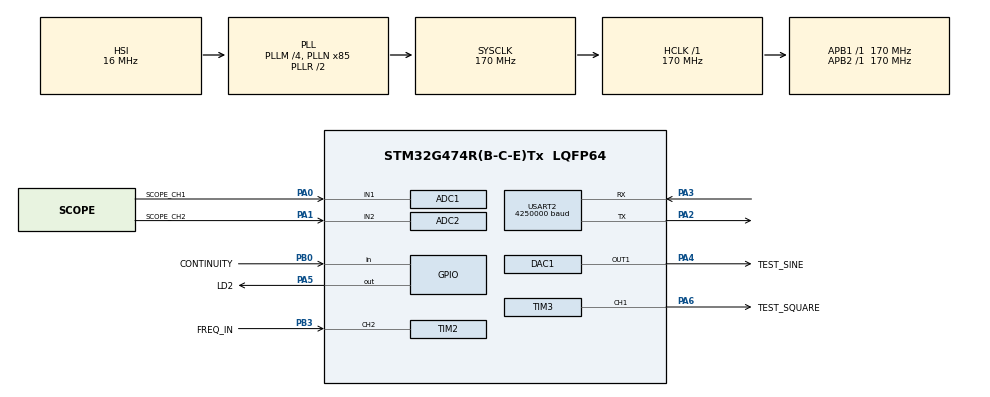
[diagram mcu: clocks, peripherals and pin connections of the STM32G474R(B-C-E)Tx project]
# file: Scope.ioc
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ADC1.Channel-0\#ChannelRegularConversion=ADC_CHANNEL_1
ADC1.ClockPrescaler=ADC_CLOCK_SYNC_PCLK_DIV4
ADC1.ContinuousConvMode=DISABLE
ADC1.DMAContinuousRequests=DISABLE
ADC1.DataAlign=ADC_DATAALIGN_RIGHT
ADC1.DiscontinuousConvMode=DISABLE
ADC1.EOCSelection=ADC_EOC_SINGLE_CONV
ADC1.EnableInjectedConversion=DISABLE
ADC1.EnableRegularConversion=ENABLE
ADC1.ExternalTrigConv=ADC_EXTERNALTRIG_T6_TRGO
ADC1.ExternalTrigConvEdge=ADC_EXTERNALTRIGCONVEDGE_RISING
ADC1.LowPowerAutoWait=DISABLE
ADC1.Mode=ADC_MODE_INDEPENDENT
ADC1.NbrOfConversion=1
ADC1.OffsetNumber-0\#ChannelRegularConversion=ADC_OFFSET_NONE
ADC1.Overrun=ADC_OVR_DATA_OVERWRITTEN
ADC1.OversamplingMode=DISABLE
ADC1.Rank-0\#ChannelRegularConversion=1
ADC1.Resolution=ADC_RESOLUTION_12B
ADC1.SamplingTime-0\#ChannelRegularConversion=ADC_SAMPLETIME_6CYCLES_5
ADC1.ScanConvMode=ADC_SCAN_DISABLE
ADC1.master=1
ADC2.Channel-0\#ChannelRegularConversion=ADC_CHANNEL_2
ADC2.ClockPrescaler=ADC_CLOCK_SYNC_PCLK_DIV4
ADC2.ContinuousConvMode=DISABLE
ADC2.DMAContinuousRequests=DISABLE
ADC2.DataAlign=ADC_DATAALIGN_RIGHT
ADC2.DiscontinuousConvMode=DISABLE
ADC2.EOCSelection=ADC_EOC_SINGLE_CONV
ADC2.EnableInjectedConversion=DISABLE
ADC2.EnableRegularConversion=ENABLE
ADC2.ExternalTrigConv=ADC_EXTERNALTRIG_T6_TRGO
ADC2.ExternalTrigConvEdge=ADC_EXTERNALTRIGCONVEDGE_RISING
ADC2.LowPowerAutoWait=DISABLE
ADC2.NbrOfConversion=1
ADC2.OffsetNumber-0\#ChannelRegularConversion=ADC_OFFSET_NONE
ADC2.Overrun=ADC_OVR_DATA_OVERWRITTEN
ADC2.OversamplingMode=DISABLE
ADC2.Rank-0\#ChannelRegularConversion=1
ADC2.Resolution=ADC_RESOLUTION_12B
ADC2.SamplingTime-0\#ChannelRegularConversion=ADC_SAMPLETIME_6CYCLES_5
ADC2.ScanConvMode=ADC_SCAN_DISABLE
ADC5.Channel-0\#ChannelRegularConversion=ADC_CHANNEL_VREFINT
ADC5.ClockPrescaler=ADC_CLOCK_SYNC_PCLK_DIV4
ADC5.ContinuousConvMode=DISABLE
ADC5.ExternalTrigConv=ADC_SOFTWARE_START
ADC5.NbrOfConversion=1
ADC5.OffsetNumber-0\#ChannelRegularConversion=ADC_OFFSET_NONE
ADC5.Rank-0\#ChannelRegularConversion=1
ADC5.SamplingTime-0\#ChannelRegularConversion=ADC_SAMPLETIME_640CYCLES_5
DAC1.DAC_Trigger_OUT1-DAC_OUT1=DAC_TRIGGER_T7_TRGO
Dma.ADC1.0.Direction=DMA_PERIPH_TO_MEMORY
Dma.ADC1.0.EventEnable=DISABLE
Dma.ADC1.0.Instance=DMA1_Channel1
Dma.ADC1.0.MemDataAlignment=DMA_MDATAALIGN_HALFWORD
Dma.ADC1.0.MemInc=DMA_MINC_ENABLE
Dma.ADC1.0.Mode=DMA_NORMAL
Dma.ADC1.0.PeriphDataAlignment=DMA_PDATAALIGN_HALFWORD
Dma.ADC1.0.PeriphInc=DMA_PINC_DISABLE
Dma.ADC1.0.Polarity=HAL_DMAMUX_REQ_GEN_RISING
Dma.ADC1.0.Priority=DMA_PRIORITY_HIGH
Dma.ADC1.0.RequestNumber=1
Dma.ADC1.0.SignalID=NONE
Dma.ADC1.0.SyncEnable=DISABLE
Dma.ADC1.0.SyncPolarity=HAL_DMAMUX_SYNC_NO_EVENT
Dma.ADC1.0.SyncRequestNumber=1
Dma.ADC1.0.SyncSignalID=NONE
Dma.ADC2.1.Direction=DMA_PERIPH_TO_MEMORY
Dma.ADC2.1.EventEnable=DISABLE
Dma.ADC2.1.Instance=DMA1_Channel2
Dma.ADC2.1.MemDataAlignment=DMA_MDATAALIGN_HALFWORD
Dma.ADC2.1.MemInc=DMA_MINC_ENABLE
Dma.ADC2.1.Mode=DMA_NORMAL
Dma.ADC2.1.PeriphDataAlignment=DMA_PDATAALIGN_HALFWORD
Dma.ADC2.1.PeriphInc=DMA_PINC_DISABLE
Dma.ADC2.1.Polarity=HAL_DMAMUX_REQ_GEN_RISING
Dma.ADC2.1.Priority=DMA_PRIORITY_HIGH
Dma.ADC2.1.RequestNumber=1
Dma.ADC2.1.SignalID=NONE
Dma.ADC2.1.SyncEnable=DISABLE
Dma.ADC2.1.SyncPolarity=HAL_DMAMUX_SYNC_NO_EVENT
Dma.ADC2.1.SyncRequestNumber=1
Dma.ADC2.1.SyncSignalID=NONE
Dma.DAC1_CH1.2.Direction=DMA_MEMORY_TO_PERIPH
Dma.DAC1_CH1.2.EventEnable=DISABLE
Dma.DAC1_CH1.2.Instance=DMA1_Channel3
Dma.DAC1_CH1.2.MemDataAlignment=DMA_MDATAALIGN_HALFWORD
Dma.DAC1_CH1.2.MemInc=DMA_MINC_ENABLE
Dma.DAC1_CH1.2.Mode=DMA_CIRCULAR
Dma.DAC1_CH1.2.PeriphDataAlignment=DMA_PDATAALIGN_WORD
Dma.DAC1_CH1.2.PeriphInc=DMA_PINC_DISABLE
Dma.DAC1_CH1.2.Polarity=HAL_DMAMUX_REQ_GEN_RISING
Dma.DAC1_CH1.2.Priority=DMA_PRIORITY_LOW
Dma.DAC1_CH1.2.RequestNumber=1
Dma.DAC1_CH1.2.SignalID=NONE
Dma.DAC1_CH1.2.SyncEnable=DISABLE
Dma.DAC1_CH1.2.SyncPolarity=HAL_DMAMUX_SYNC_NO_EVENT
Dma.DAC1_CH1.2.SyncRequestNumber=1
Dma.DAC1_CH1.2.SyncSignalID=NONE
Dma.Request0=ADC1
Dma.Request1=ADC2
Dma.Request2=DAC1_CH1
Mcu.Family=STM32G4
Mcu.Name=STM32G474R(B-C-E)Tx
Mcu.Package=LQFP64
NVIC.DMA1_Channel1_IRQn=true\:0\:0\:false\:false\:true\:false\:true\:true
NVIC.DMA1_Channel2_IRQn=true\:0\:0\:false\:false\:true\:false\:true\:true
NVIC.DMA1_Channel3_IRQn=true\:0\:0\:false\:false\:true\:false\:true\:true
NVIC.PriorityGroup=NVIC_PRIORITYGROUP_4
NVIC.USART2_IRQn=true\:0\:0\:false\:false\:true\:true\:true\:true
PA0.GPIO_Label=SCOPE_CH1
PA0.Mode=IN1-Single-Ended
PA0.Signal=ADC1_IN1
PA1.GPIO_Label=SCOPE_CH2
PA1.Mode=IN2-Single-Ended
PA1.Signal=ADC2_IN2
PA2.Mode=Asynchronous
PA2.Signal=USART2_TX
PA3.Mode=Asynchronous
PA3.Signal=USART2_RX
PA4.GPIO_Label=TEST_SINE
PA4.Signal=COMP_DAC11_group
PA5.GPIO_Label=LD2
PA5.Signal=GPIO_Output
PA6.GPIO_Label=TEST_SQUARE
PA6.Signal=S_TIM3_CH1
PB0.GPIO_Label=CONTINUITY
PB0.GPIO_PuPd=GPIO_PULLUP
PB0.Signal=GPIO_Input
PB3.GPIO_Label=FREQ_IN
PB3.GPIO_PuPd=GPIO_PULLDOWN
PB3.Signal=S_TIM2_CH2
ProjectManager.HeapSize=0x200
ProjectManager.StackSize=0x800
ProjectManager.TargetToolchain=STM32CubeIDE
RCC.ADC12Freq_Value=170000000
RCC.ADC345Freq_Value=170000000
RCC.AHBFreq_Value=170000000
RCC.APB1Freq_Value=170000000
RCC.APB1TimFreq_Value=170000000
RCC.APB2Freq_Value=170000000
RCC.APB2TimFreq_Value=170000000
RCC.CortexFreq_Value=170000000
RCC.EXTERNAL_CLOCK_VALUE=12288000
RCC.HCLKFreq_Value=170000000
RCC.HSE_VALUE=8000000
RCC.HSI48_VALUE=48000000
RCC.HSI_VALUE=16000000
RCC.LSE_VALUE=32768
RCC.PLLM=RCC_PLLM_DIV4
RCC.PLLN=85
RCC.SYSCLKFreq_VALUE=170000000
RCC.SYSCLKSource=RCC_SYSCLKSOURCE_PLLCLK
RCC.USBFreq_Value=170000000
RCC.VCOOutputFreq_Value=340000000
SH.COMP_DAC11_group.0=DAC1_OUT1,DAC_OUT1
SH.S_TIM2_CH2.0=TIM2_CH2,TriggerSource_TI2FP2
SH.S_TIM2_CH2.1=TIM2_CH2,Input_Capture2_from_TI2
SH.S_TIM2_CH2.2=TIM2_CH2,Input_Capture1_from_TI2
SH.S_TIM3_CH1.0=TIM3_CH1,PWM Generation1 CH1
TIM2.Channel-Input_Capture1_from_TI2=TIM_CHANNEL_1
TIM2.Channel-Input_Capture2_from_TI2=TIM_CHANNEL_2
TIM2.ICPolarity_CH1=TIM_INPUTCHANNELPOLARITY_FALLING
TIM2.ICPolarity_CH2=TIM_INPUTCHANNELPOLARITY_RISING
TIM2.ICSelection-Input_Capture1_from_TI2=TIM_ICSELECTION_INDIRECTTI
TIM2.ICSelection-Input_Capture2_from_TI2=TIM_ICSELECTION_DIRECTTI
TIM2.Period=4294967295
TIM2.Prescaler=0
TIM2.TIM_SlaveMode=TIM_SLAVEMODE_RESET
TIM3.Channel-PWM\ Generation1\ CH1=TIM_CHANNEL_1
TIM3.PeriodNoDither=4999
TIM3.Prescaler=16
TIM3.PulseNoDither_1=1250
TIM6.PeriodNoDither=9
TIM6.Prescaler=16
TIM6.TIM_MasterOutputTrigger=TIM_TRGO_UPDATE
TIM7.PeriodNoDither=1699
TIM7.Prescaler=0
TIM7.TIM_MasterOutputTrigger=TIM_TRGO_UPDATE
USART2.BaudRate=4250000
USART2.VirtualMode-Asynchronous=VM_ASYNC
VP_ADC5_Vref_Input.Mode=IN-Vrefint
VP_SYS_VS_DBSignals.Mode=DisableDeadBatterySignals
VP_TIM2_VS_ControllerModeReset.Mode=Reset Mode
VP_TIM3_VS_ClockSourceINT.Mode=Internal
VP_TIM6_VS_ClockSourceINT.Mode=Enable_Timer
VP_TIM7_VS_ClockSourceINT.Mode=Enable_Timer
board=custom

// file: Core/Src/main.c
/* USER CODE BEGIN Header */
/**
  ******************************************************************************
  * @file           : main.c
  * @brief          : Main program body
  ******************************************************************************
  * @attention
  *
  * Copyright (c) 2026 STMicroelectronics.
  * All rights reserved.
  *
  * This software is licensed under terms that can be found in the LICENSE file
  * in the root directory of this software component.
  * If no LICENSE file comes with this software, it is provided AS-IS.
  *
  ******************************************************************************
  */
/* USER CODE END Header */
#include "main.h"

/* USER CODE BEGIN Includes */
#include "scope.h"
#include "test_signals.h"

/* USER CODE END Includes */

ADC_HandleTypeDef hadc1;
ADC_HandleTypeDef hadc2;
ADC_HandleTypeDef hadc5;
DMA_HandleTypeDef hdma_adc1;
DMA_HandleTypeDef hdma_adc2;

DAC_HandleTypeDef hdac1;
DMA_HandleTypeDef hdma_dac1_ch1;

TIM_HandleTypeDef htim2;
TIM_HandleTypeDef htim3;
TIM_HandleTypeDef htim6;
TIM_HandleTypeDef htim7;

UART_HandleTypeDef huart2;

void SystemClock_Config(void);
static void MX_GPIO_Init(void);
static void MX_DMA_Init(void);
static void MX_USART2_UART_Init(void);
static void MX_ADC1_Init(void);
static void MX_ADC2_Init(void);
static void MX_ADC5_Init(void);
static void MX_DAC1_Init(void);
static void MX_TIM2_Init(void);
static void MX_TIM3_Init(void);
static void MX_TIM6_Init(void);
static void MX_TIM7_Init(void);

int main(void)
{

  /* MCU Configuration--------------------------------------------------------*/

  /* Reset of all peripherals, Initializes the Flash interface and the Systick. */
  HAL_Init();

  /* Configure the system clock */
  SystemClock_Config();

  /* Initialize all configured peripherals */
  MX_GPIO_Init();
  MX_DMA_Init();
  MX_USART2_UART_Init();
  MX_ADC1_Init();
  MX_ADC2_Init();
  MX_ADC5_Init();
  MX_DAC1_Init();
  MX_TIM2_Init();
  MX_TIM3_Init();
  MX_TIM6_Init();
  MX_TIM7_Init();
  /* USER CODE BEGIN 2 */
  test_signals_start();   /* sine on A2, square on D12 */
  scope_init();

  /* USER CODE END 2 */

  /* Infinite loop */
  while (1)
  {

    /* USER CODE BEGIN 3 */
    scope_run();          /* measure once and send it to the PC */
  }
  /* USER CODE END 3 */
}

void SystemClock_Config(void)
{
  RCC_OscInitTypeDef RCC_OscInitStruct = {0};
  RCC_ClkInitTypeDef RCC_ClkInitStruct = {0};

  /** Configure the main internal regulator output voltage
  */
  HAL_PWREx_ControlVoltageScaling(PWR_REGULATOR_VOLTAGE_SCALE1_BOOST);

  /** Initializes the RCC Oscillators according to the specified parameters
  * in the RCC_OscInitTypeDef structure.
  */
  RCC_OscInitStruct.OscillatorType = RCC_OSCILLATORTYPE_HSI;
  RCC_OscInitStruct.HSIState = RCC_HSI_ON;
  RCC_OscInitStruct.HSICalibrationValue = RCC_HSICALIBRATION_DEFAULT;
  RCC_OscInitStruct.PLL.PLLState = RCC_PLL_ON;
  RCC_OscInitStruct.PLL.PLLSource = RCC_PLLSOURCE_HSI;
  RCC_OscInitStruct.PLL.PLLM = RCC_PLLM_DIV4;
  RCC_OscInitStruct.PLL.PLLN = 85;
  RCC_OscInitStruct.PLL.PLLP = RCC_PLLP_DIV2;
  RCC_OscInitStruct.PLL.PLLQ = RCC_PLLQ_DIV2;
  RCC_OscInitStruct.PLL.PLLR = RCC_PLLR_DIV2;
  if (HAL_RCC_OscConfig(&RCC_OscInitStruct) != HAL_OK)
  {
    Error_Handler();
  }

  /** Initializes the CPU, AHB and APB buses clocks
  */
  RCC_ClkInitStruct.ClockType = RCC_CLOCKTYPE_HCLK|RCC_CLOCKTYPE_SYSCLK
                              |RCC_CLOCKTYPE_PCLK1|RCC_CLOCKTYPE_PCLK2;
  RCC_ClkInitStruct.SYSCLKSource = RCC_SYSCLKSOURCE_PLLCLK;
  RCC_ClkInitStruct.AHBCLKDivider = RCC_SYSCLK_DIV1;
  RCC_ClkInitStruct.APB1CLKDivider = RCC_HCLK_DIV1;
  RCC_ClkInitStruct.APB2CLKDivider = RCC_HCLK_DIV1;

  if (HAL_RCC_ClockConfig(&RCC_ClkInitStruct, FLASH_LATENCY_4) != HAL_OK)
  {
    Error_Handler();
  }
}

static void MX_ADC1_Init(void)
{

  ADC_MultiModeTypeDef multimode = {0};
  ADC_ChannelConfTypeDef sConfig = {0};

  /** Common config
  */
  hadc1.Instance = ADC1;
  hadc1.Init.ClockPrescaler = ADC_CLOCK_SYNC_PCLK_DIV4;
  hadc1.Init.Resolution = ADC_RESOLUTION_12B;
  hadc1.Init.DataAlign = ADC_DATAALIGN_RIGHT;
  hadc1.Init.GainCompensation = 0;
  hadc1.Init.ScanConvMode = ADC_SCAN_DISABLE;
  hadc1.Init.EOCSelection = ADC_EOC_SINGLE_CONV;
  hadc1.Init.LowPowerAutoWait = DISABLE;
  hadc1.Init.ContinuousConvMode = DISABLE;
  hadc1.Init.NbrOfConversion = 1;
  hadc1.Init.DiscontinuousConvMode = DISABLE;
  hadc1.Init.ExternalTrigConv = ADC_EXTERNALTRIG_T6_TRGO;
  hadc1.Init.ExternalTrigConvEdge = ADC_EXTERNALTRIGCONVEDGE_RISING;
  hadc1.Init.DMAContinuousRequests = DISABLE;
  hadc1.Init.Overrun = ADC_OVR_DATA_OVERWRITTEN;
  hadc1.Init.OversamplingMode = DISABLE;
  if (HAL_ADC_Init(&hadc1) != HAL_OK)
  {
    Error_Handler();
  }

  /** Configure the ADC multi-mode
  */
  multimode.Mode = ADC_MODE_INDEPENDENT;
  if (HAL_ADCEx_MultiModeConfigChannel(&hadc1, &multimode) != HAL_OK)
  {
    Error_Handler();
  }

  /** Configure Regular Channel
  */
  sConfig.Channel = ADC_CHANNEL_1;
  sConfig.Rank = ADC_REGULAR_RANK_1;
  sConfig.SamplingTime = ADC_SAMPLETIME_6CYCLES_5;
  sConfig.SingleDiff = ADC_SINGLE_ENDED;
  sConfig.OffsetNumber = ADC_OFFSET_NONE;
  sConfig.Offset = 0;
  if (HAL_ADC_ConfigChannel(&hadc1, &sConfig) != HAL_OK)
  {
    Error_Handler();
  }

}

static void MX_ADC2_Init(void)
{

  ADC_ChannelConfTypeDef sConfig = {0};

  /** Common config
  */
  hadc2.Instance = ADC2;
  hadc2.Init.ClockPrescaler = ADC_CLOCK_SYNC_PCLK_DIV4;
  hadc2.Init.Resolution = ADC_RESOLUTION_12B;
  hadc2.Init.DataAlign = ADC_DATAALIGN_RIGHT;
  hadc2.Init.GainCompensation = 0;
  hadc2.Init.ScanConvMode = ADC_SCAN_DISABLE;
  hadc2.Init.EOCSelection = ADC_EOC_SINGLE_CONV;
  hadc2.Init.LowPowerAutoWait = DISABLE;
  hadc2.Init.ContinuousConvMode = DISABLE;
  hadc2.Init.NbrOfConversion = 1;
  hadc2.Init.DiscontinuousConvMode = DISABLE;
  hadc2.Init.ExternalTrigConv = ADC_EXTERNALTRIG_T6_TRGO;
  hadc2.Init.ExternalTrigConvEdge = ADC_EXTERNALTRIGCONVEDGE_RISING;
  hadc2.Init.DMAContinuousRequests = DISABLE;
  hadc2.Init.Overrun = ADC_OVR_DATA_OVERWRITTEN;
  hadc2.Init.OversamplingMode = DISABLE;
  if (HAL_ADC_Init(&hadc2) != HAL_OK)
  {
    Error_Handler();
  }

  /** Configure Regular Channel
  */
  sConfig.Channel = ADC_CHANNEL_2;
  sConfig.Rank = ADC_REGULAR_RANK_1;
  sConfig.SamplingTime = ADC_SAMPLETIME_6CYCLES_5;
  sConfig.SingleDiff = ADC_SINGLE_ENDED;
  sConfig.OffsetNumber = ADC_OFFSET_NONE;
  sConfig.Offset = 0;
  if (HAL_ADC_ConfigChannel(&hadc2, &sConfig) != HAL_OK)
  {
    Error_Handler();
  }

}

static void MX_ADC5_Init(void)
{

  ADC_ChannelConfTypeDef sConfig = {0};

  /** Common config
  */
  hadc5.Instance = ADC5;
  hadc5.Init.ClockPrescaler = ADC_CLOCK_SYNC_PCLK_DIV4;
  hadc5.Init.Resolution = ADC_RESOLUTION_12B;
  hadc5.Init.DataAlign = ADC_DATAALIGN_RIGHT;
  hadc5.Init.GainCompensation = 0;
  hadc5.Init.ScanConvMode = ADC_SCAN_DISABLE;
  hadc5.Init.EOCSelection = ADC_EOC_SINGLE_CONV;
  hadc5.Init.LowPowerAutoWait = DISABLE;
  hadc5.Init.ContinuousConvMode = DISABLE;
  hadc5.Init.NbrOfConversion = 1;
  hadc5.Init.DiscontinuousConvMode = DISABLE;
  hadc5.Init.ExternalTrigConv = ADC_SOFTWARE_START;
  hadc5.Init.ExternalTrigConvEdge = ADC_EXTERNALTRIGCONVEDGE_NONE;
  hadc5.Init.DMAContinuousRequests = DISABLE;
  hadc5.Init.Overrun = ADC_OVR_DATA_PRESERVED;
  hadc5.Init.OversamplingMode = DISABLE;
  if (HAL_ADC_Init(&hadc5) != HAL_OK)
  {
    Error_Handler();
  }

  /** Configure Regular Channel
  */
  sConfig.Channel = ADC_CHANNEL_VREFINT;
  sConfig.Rank = ADC_REGULAR_RANK_1;
  sConfig.SamplingTime = ADC_SAMPLETIME_640CYCLES_5;
  sConfig.SingleDiff = ADC_SINGLE_ENDED;
  sConfig.OffsetNumber = ADC_OFFSET_NONE;
  sConfig.Offset = 0;
  if (HAL_ADC_ConfigChannel(&hadc5, &sConfig) != HAL_OK)
  {
    Error_Handler();
  }

}

static void MX_DAC1_Init(void)
{

  DAC_ChannelConfTypeDef sConfig = {0};

  /** DAC Initialization
  */
  hdac1.Instance = DAC1;
  if (HAL_DAC_Init(&hdac1) != HAL_OK)
  {
    Error_Handler();
  }

  /** DAC channel OUT1 config
  */
  sConfig.DAC_HighFrequency = DAC_HIGH_FREQUENCY_INTERFACE_MODE_AUTOMATIC;
  sConfig.DAC_DMADoubleDataMode = DISABLE;
  sConfig.DAC_SignedFormat = DISABLE;
  sConfig.DAC_SampleAndHold = DAC_SAMPLEANDHOLD_DISABLE;
  sConfig.DAC_Trigger = DAC_TRIGGER_T7_TRGO;
  sConfig.DAC_Trigger2 = DAC_TRIGGER_NONE;
  sConfig.DAC_OutputBuffer = DAC_OUTPUTBUFFER_ENABLE;
  sConfig.DAC_ConnectOnChipPeripheral = DAC_CHIPCONNECT_EXTERNAL;
  sConfig.DAC_UserTrimming = DAC_TRIMMING_FACTORY;
  if (HAL_DAC_ConfigChannel(&hdac1, &sConfig, DAC_CHANNEL_1) != HAL_OK)
  {
    Error_Handler();
  }

}

static void MX_TIM2_Init(void)
{

  TIM_SlaveConfigTypeDef sSlaveConfig = {0};
  TIM_MasterConfigTypeDef sMasterConfig = {0};
  TIM_IC_InitTypeDef sConfigIC = {0};

  htim2.Instance = TIM2;
  htim2.Init.Prescaler = 0;
  htim2.Init.CounterMode = TIM_COUNTERMODE_UP;
  htim2.Init.Period = 4294967295;
  htim2.Init.ClockDivision = TIM_CLOCKDIVISION_DIV1;
  htim2.Init.AutoReloadPreload = TIM_AUTORELOAD_PRELOAD_DISABLE;
  if (HAL_TIM_Base_Init(&htim2) != HAL_OK)
  {
    Error_Handler();
  }
  if (HAL_TIM_IC_Init(&htim2) != HAL_OK)
  {
    Error_Handler();
  }
  sSlaveConfig.SlaveMode = TIM_SLAVEMODE_RESET;
  sSlaveConfig.InputTrigger = TIM_TS_TI2FP2;
  sSlaveConfig.TriggerPolarity = TIM_INPUTCHANNELPOLARITY_RISING;
  sSlaveConfig.TriggerFilter = 0;
  if (HAL_TIM_SlaveConfigSynchro(&htim2, &sSlaveConfig) != HAL_OK)
  {
    Error_Handler();
  }
  sMasterConfig.MasterOutputTrigger = TIM_TRGO_RESET;
  sMasterConfig.MasterSlaveMode = TIM_MASTERSLAVEMODE_DISABLE;
  if (HAL_TIMEx_MasterConfigSynchronization(&htim2, &sMasterConfig) != HAL_OK)
  {
    Error_Handler();
  }
  sConfigIC.ICPolarity = TIM_INPUTCHANNELPOLARITY_FALLING;
  sConfigIC.ICSelection = TIM_ICSELECTION_INDIRECTTI;
  sConfigIC.ICPrescaler = TIM_ICPSC_DIV1;
  sConfigIC.ICFilter = 0;
  if (HAL_TIM_IC_ConfigChannel(&htim2, &sConfigIC, TIM_CHANNEL_1) != HAL_OK)
  {
    Error_Handler();
  }
  sConfigIC.ICPolarity = TIM_INPUTCHANNELPOLARITY_RISING;
  sConfigIC.ICSelection = TIM_ICSELECTION_DIRECTTI;
  if (HAL_TIM_IC_ConfigChannel(&htim2, &sConfigIC, TIM_CHANNEL_2) != HAL_OK)
  {
    Error_Handler();
  }

}

static void MX_TIM3_Init(void)
{

  TIM_ClockConfigTypeDef sClockSourceConfig = {0};
  TIM_MasterConfigTypeDef sMasterConfig = {0};
  TIM_OC_InitTypeDef sConfigOC = {0};

  htim3.Instance = TIM3;
  htim3.Init.Prescaler = 16;
  htim3.Init.CounterMode = TIM_COUNTERMODE_UP;
  htim3.Init.Period = 4999;
  htim3.Init.ClockDivision = TIM_CLOCKDIVISION_DIV1;
  htim3.Init.AutoReloadPreload = TIM_AUTORELOAD_PRELOAD_DISABLE;
  if (HAL_TIM_Base_Init(&htim3) != HAL_OK)
  {
    Error_Handler();
  }
  sClockSourceConfig.ClockSource = TIM_CLOCKSOURCE_INTERNAL;
  if (HAL_TIM_ConfigClockSource(&htim3, &sClockSourceConfig) != HAL_OK)
  {
    Error_Handler();
  }
  if (HAL_TIM_PWM_Init(&htim3) != HAL_OK)
  {
    Error_Handler();
  }
  sMasterConfig.MasterOutputTrigger = TIM_TRGO_RESET;
  sMasterConfig.MasterSlaveMode = TIM_MASTERSLAVEMODE_DISABLE;
  if (HAL_TIMEx_MasterConfigSynchronization(&htim3, &sMasterConfig) != HAL_OK)
  {
    Error_Handler();
  }
  sConfigOC.OCMode = TIM_OCMODE_PWM1;
  sConfigOC.Pulse = 1250;
  sConfigOC.OCPolarity = TIM_OCPOLARITY_HIGH;
  sConfigOC.OCFastMode = TIM_OCFAST_DISABLE;
  if (HAL_TIM_PWM_ConfigChannel(&htim3, &sConfigOC, TIM_CHANNEL_1) != HAL_OK)
  {
    Error_Handler();
  }
  HAL_TIM_MspPostInit(&htim3);

}

static void MX_TIM6_Init(void)
{

  TIM_MasterConfigTypeDef sMasterConfig = {0};

  htim6.Instance = TIM6;
  htim6.Init.Prescaler = 16;
  htim6.Init.CounterMode = TIM_COUNTERMODE_UP;
  htim6.Init.Period = 9;
  htim6.Init.AutoReloadPreload = TIM_AUTORELOAD_PRELOAD_DISABLE;
  if (HAL_TIM_Base_Init(&htim6) != HAL_OK)
  {
    Error_Handler();
  }
  sMasterConfig.MasterOutputTrigger = TIM_TRGO_UPDATE;
  sMasterConfig.MasterSlaveMode = TIM_MASTERSLAVEMODE_DISABLE;
  if (HAL_TIMEx_MasterConfigSynchronization(&htim6, &sMasterConfig) != HAL_OK)
  {
    Error_Handler();
  }

}

static void MX_TIM7_Init(void)
{

  TIM_MasterConfigTypeDef sMasterConfig = {0};

  htim7.Instance = TIM7;
  htim7.Init.Prescaler = 0;
  htim7.Init.CounterMode = TIM_COUNTERMODE_UP;
  htim7.Init.Period = 1699;
  htim7.Init.AutoReloadPreload = TIM_AUTORELOAD_PRELOAD_DISABLE;
  if (HAL_TIM_Base_Init(&htim7) != HAL_OK)
  {
    Error_Handler();
  }
  sMasterConfig.MasterOutputTrigger = TIM_TRGO_UPDATE;
  sMasterConfig.MasterSlaveMode = TIM_MASTERSLAVEMODE_DISABLE;
  if (HAL_TIMEx_MasterConfigSynchronization(&htim7, &sMasterConfig) != HAL_OK)
  {
    Error_Handler();
  }

}

static void MX_USART2_UART_Init(void)
{

  huart2.Instance = USART2;
  huart2.Init.BaudRate = 4250000;
  huart2.Init.WordLength = UART_WORDLENGTH_8B;
  huart2.Init.StopBits = UART_STOPBITS_1;
  huart2.Init.Parity = UART_PARITY_NONE;
  huart2.Init.Mode = UART_MODE_TX_RX;
  huart2.Init.HwFlowCtl = UART_HWCONTROL_NONE;
  huart2.Init.OverSampling = UART_OVERSAMPLING_16;
  huart2.Init.OneBitSampling = UART_ONE_BIT_SAMPLE_DISABLE;
  huart2.Init.ClockPrescaler = UART_PRESCALER_DIV1;
  huart2.AdvancedInit.AdvFeatureInit = UART_ADVFEATURE_NO_INIT;
  if (HAL_UART_Init(&huart2) != HAL_OK)
  {
    Error_Handler();
  }
  if (HAL_UARTEx_SetTxFifoThreshold(&huart2, UART_TXFIFO_THRESHOLD_1_8) != HAL_OK)
  {
    Error_Handler();
  }
  if (HAL_UARTEx_SetRxFifoThreshold(&huart2, UART_RXFIFO_THRESHOLD_1_8) != HAL_OK)
  {
    Error_Handler();
  }
  if (HAL_UARTEx_DisableFifoMode(&huart2) != HAL_OK)
  {
    Error_Handler();
  }

}

static void MX_DMA_Init(void)
{

  /* DMA controller clock enable */
  __HAL_RCC_DMAMUX1_CLK_ENABLE();
  __HAL_RCC_DMA1_CLK_ENABLE();

  /* DMA interrupt init */
  /* DMA1_Channel1_IRQn interrupt configuration */
  HAL_NVIC_SetPriority(DMA1_Channel1_IRQn, 0, 0);
  HAL_NVIC_EnableIRQ(DMA1_Channel1_IRQn);
  /* DMA1_Channel2_IRQn interrupt configuration */
  HAL_NVIC_SetPriority(DMA1_Channel2_IRQn, 0, 0);
  HAL_NVIC_EnableIRQ(DMA1_Channel2_IRQn);
  /* DMA1_Channel3_IRQn interrupt configuration */
  HAL_NVIC_SetPriority(DMA1_Channel3_IRQn, 0, 0);
  HAL_NVIC_EnableIRQ(DMA1_Channel3_IRQn);

}

static void MX_GPIO_Init(void)
{
  GPIO_InitTypeDef GPIO_InitStruct = {0};

  /* GPIO Ports Clock Enable */
  __HAL_RCC_GPIOA_CLK_ENABLE();
  __HAL_RCC_GPIOB_CLK_ENABLE();

  /*Configure GPIO pin Output Level */
  HAL_GPIO_WritePin(LD2_GPIO_Port, LD2_Pin, GPIO_PIN_RESET);

  /*Configure GPIO pin : LD2_Pin */
  GPIO_InitStruct.Pin = LD2_Pin;
  GPIO_InitStruct.Mode = GPIO_MODE_OUTPUT_PP;
  GPIO_InitStruct.Pull = GPIO_NOPULL;
  GPIO_InitStruct.Speed = GPIO_SPEED_FREQ_LOW;
  HAL_GPIO_Init(LD2_GPIO_Port, &GPIO_InitStruct);

  /*Configure GPIO pin : CONTINUITY_Pin */
  GPIO_InitStruct.Pin = CONTINUITY_Pin;
  GPIO_InitStruct.Mode = GPIO_MODE_INPUT;
  GPIO_InitStruct.Pull = GPIO_PULLUP;
  HAL_GPIO_Init(CONTINUITY_GPIO_Port, &GPIO_InitStruct);

}

void Error_Handler(void)
{
  __disable_irq();
  while (1)
  {
  }
}
